# evalsoc register map
Vendor: Nuclei; Series: Nuclei Evaluation SoC
CPU: Evalsoc, little endian
Registers are 32-bit, read-write, reset 0x0 unless marked. A register's access mark holds for its fields unless they carry their own. Offsets are from the block's base; [hi:lo] are bit positions; {n}, {i} and the like mark numbered series; 'fields as' and 'values as' point back to an identical list.

## SMP — Address space of SMP and Cluster Cache. Nuclei Processor Core can optionally support Cluster Cache (CC) and Symmetric Multi-Processor (SMP).
Base 0x18040000
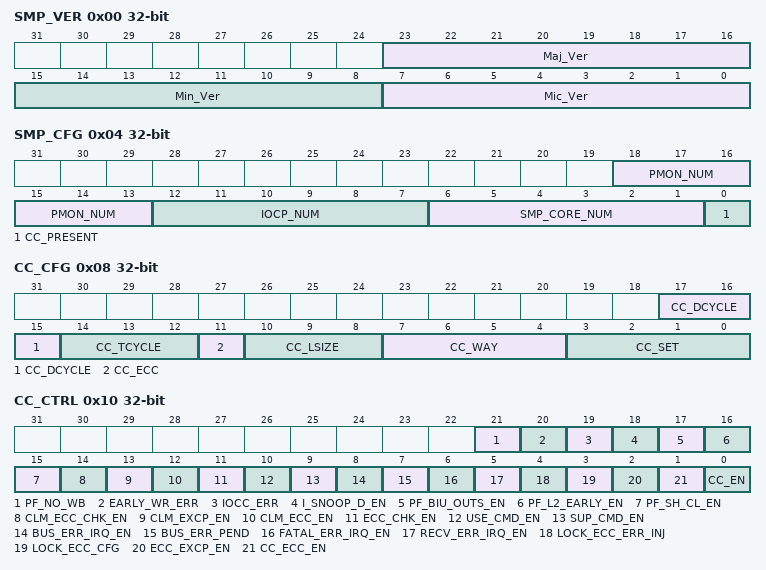
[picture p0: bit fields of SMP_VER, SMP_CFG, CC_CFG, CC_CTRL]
0x00 SMP_VER ro — Machine Mode SMP Version Register. Shows the microarchitecture implementation version of SMP related module.
  [23:16] Maj_Ver — Major Version Number
  [15:8] Min_Ver — Minor Version Number
  [7:0] Mic_Ver — Micro Version Number
0x04 SMP_CFG ro — Machine Mode SMP Configuration Register. Shows the hardware configuration of SMP related design.
  [18:13] PMON_NUM — The performance monitor number, it is fixed value when the RTL is generated.
  [12:7] IOCP_NUM — The IO Coherency port number in the cluster, it is fixed value when the RTL is generated.
  [6:1] SMP_CORE_NUM — Indicate core number in the cluster, it is fixed value (smp_core_num -1) when the RTL is generated.
  [0] CC_PRESENT — Cluster Cache present or not. 0: not present; 1: Present
0x08 CC_CFG ro — Machine Mode CC Config Register. Shows the hardware configuration of Cluster Cache.
  [17:15] CC_DCYCLE — Indicate the L2 Data sram access cycle - 1. 0: 1-cycle, 1: 2-cycle
  [14:12] CC_TCYCLE — Indicate the L2 Tag sram access cycle - 1. 0: 1-cycle, 1: 2-cycle
  [11] CC_ECC — Indicate the Cluster Cache supports ECC or not
  [10:8] CC_LSIZE — Cluster Cache Line Size = 2^(CC_LSIZE + 2)
  [7:4] CC_WAY — Cluster Cache Way Number = (CC_WAY + 1)
  [3:0] CC_SET — Cluster Cache Set Number = 2^(CC_SET)
0x0C SMP_ENB — Machine Mode SMP Enable Register. Controls which cores or all IOCP in the cluster can be cache coherency with each other handled by hardware.
  [15:0] SMP_Enable — SMP Enable Bit for clients in the Cluster. Each bit control one client. The low bit is CORE clients, high bit is IOCP clients.
0x10 CC_CTRL — Machine Mode CC Control Register. Controls Cluster Cache specific functions and gets some status.
  [21] PF_NO_WB — Enable L2 prefetch to abort and avoid dirty cacheline write back. 0: Disable, 1: Enable
  [20] EARLY_WR_ERR ro — Early write response has error. 0: No error, 1: Error
  [19] IOCC_ERR ro — IOCC Has error. 0: No error, 1: Error
  [18] I_SNOOP_D_EN — Snoop to dcache for icache refill reads Enable. 0: Disable, 1: Enable (default in smp cores)
  [17] PF_BIU_OUTS_EN — Enable the limit of outstanding L2 Prefetch. 0: Disable, 1: Enable
  [16] PF_L2_EARLY_EN — Enable L2 prefetch to initialize external bus read access while lookup the cluster cache. 0: Disable, 1: Enable
  [15] PF_SH_CL_EN — Enable L1 prefetch to snoop and share cacheline from other cores. 0: Disable, 1: Enable
  [14] CLM_ECC_CHK_EN — CLM ECC Check Enable Bit. 0: Disable, 1: Enable
  [13] CLM_EXCP_EN — CLM ECC Exception Enable Bit. 0: Disable, 1: Enable
  [12] CLM_ECC_EN — CLM ECC Enable Bit. 0: Disable, 1: Enable
  [11] ECC_CHK_EN — CC ECC Check Enable Bit. 0: Disable, 1: Enable
  [10] USE_CMD_EN — Enable U Mode can operate register CC_uCMD and SMP_PMON_SEL. 0: Disable, 1: Enable
  [9] SUP_CMD_EN — Enable S Mode can operate register CC_sCMD and SMP_PMON_SEL. 0: Disable, 1: Enable
  [8] BUS_ERR_IRQ_EN — Enable the Bus Error interrupt of CC maintain operation. 0: Disable, 1: Enable
  [7] BUS_ERR_PEND ro — Indicate if there is Bus Error Pending of all type. 0: No Pending, 1: Pending.
  [6] FATAL_ERR_IRQ_EN — Enable the interrupt when fatal error count exceeds the threshold. 0: Disable, 1: Enable
  [5] RECV_ERR_IRQ_EN — Enable the interrupt when recoverable error count exceeds the threshold. 0: Disable, 1: Enable
  [4] LOCK_ECC_ERR_INJ — Lock CC ECC Error Injection Register. 0: Disable, 1: Enable.
  [3] LOCK_ECC_CFG — Lock the CC ECC Configuration Bit. 0: Disable, 1: Enable. If set to 1, previous bits can't be changed.
  [2] ECC_EXCP_EN — CC ECC Exception Enable Bit. 0: Disable, 1: Enable
  [1] CC_ECC_EN — CC ECC Enable Bit. 0: Disable, 1: Enable
  [0] CC_EN — CC Enable Bit. 0: Disable, 1: Enable
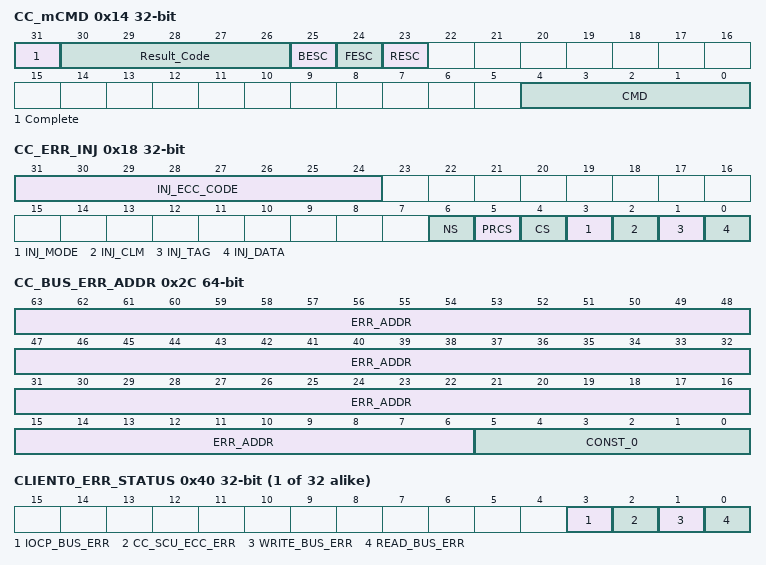
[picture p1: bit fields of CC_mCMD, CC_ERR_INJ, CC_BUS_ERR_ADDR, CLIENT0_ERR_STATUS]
0x14 CC_mCMD — Machine Mode CC Command and Status. Sets specific maintain command for Cluster Cache and checks the command result in Machine Mode.
  [31] Complete ro — Indicate the CMD complete or not. 0: Not Complete, 1: Complete
  [30:26] Result_Code ro — Result of the CMD
  [25] BESC — Read as BUS_ERR_PEND, write 1 will clear BUS_ERR_PEND.
  [24] FESC — Read as Fatal ECC Error IRQ Pending, write 1 will clear CC_FATAL_CNT.
  [23] RESC — Read as Recoverable ECC Error IRQ Pending, write 1 will clear CC_RECV_CNT.
  [4:0] CMD — Cluster Cache Maintain Command Code
0x18 CC_ERR_INJ — CC ECC Error Injection Control Register.
  [31:24] INJ_ECC_CODE — The content which will be injected
  [6] NS — Secure mode and Non secure mode. 0: secure mode, 1: non secure mode
  [5] PRCS ro — Precise injection error flag.
  [4] CS — Precise injection error control and status. Write 1 to start, automatic cleared when finished.
  [3] INJ_MODE — Indicate the software ecc code inject mode. 0: Direct Write Mode, 1: XOR Write Mode.
  [2] INJ_CLM — Inject error to CLM Ram
  [1] INJ_TAG — Inject error to CC Tag Ram
  [0] INJ_DATA — Inject error to CC Data Ram
0x1C CC_RECV_CNT — CC ECC Recoverable Error Count Register. Counts the Cluster Cache ECC recoverable error events.
  [15:0] CNT — Count the recoverable error, it is saturated
0x20 CC_FATAL_CNT — CC ECC Fatal Error Count Register. Counts the Cluster Cache ECC fatal error events.
  [15:0] CNT — Count the fatal error, it is saturated
0x24 CC_RECV_THV — CC ECC Recoverable Error Threshold Register. Sets the threshold value of Cluster Cache ECC recoverable errors.
  [15:0] THRESHOLD — The threshold value of ECC recoverable error.
0x28 CC_FATAL_THV — CC ECC Fatal Error Threshold Register. Sets the threshold value of Cluster Cache ECC fatal error.
  [15:0] THRESHOLD — The threshold value of ECC fatal error.
0x2C CC_BUS_ERR_ADDR 64-bit (reset mask 0xFFFFFFFF) — CC Maintain Operate Bus Error Physical Address. Records the Physical Address when CC Management Operation causes Bus Error.
  [63:6] ERR_ADDR — The error address when Bus Error happens.
  [5:0] CONST_0 ro — Constant 0. Width depends on cache line size.
{0x40+4i} CLIENT{i}_ERR_STATUS (i=0..31) — Client{i} of CC Error Status. Records the detail error type for the client.
  [3] IOCP_BUS_ERR — The error type is IOCP Bus response error. Only applies to clients hooked to IOCP Ports.
  [2] CC_SCU_ECC_ERR — The error type is cluster cache tag/data, SCU shadow tag or snoop L1 access ECC error.
  [1] WRITE_BUS_ERR — The error type is write bus error.
  [0] READ_BUS_ERR — The error type is read bus error.
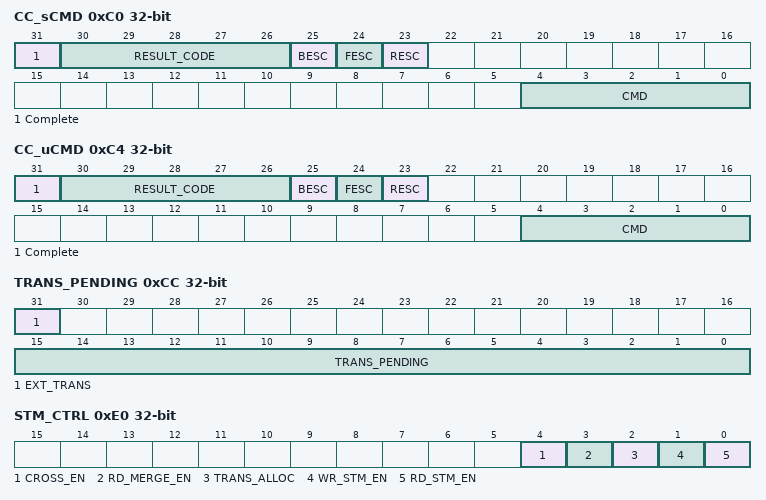
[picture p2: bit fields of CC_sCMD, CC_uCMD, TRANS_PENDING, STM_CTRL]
0xC0 CC_sCMD — Supervisor Mode CC Command and Status. Sets specific maintain command for Cluster Cache and checks the command result in Supervisor Mode.
  [31] Complete ro — Indicate the CMD complete or not. 0: Not Complete, 1: Complete
  [30:26] RESULT_CODE ro — Result of the CMD
  [25] BESC — Read as BUS_ERR_PEND, write 1 will clear BUS_ERR_PEND.
  [24] FESC — Read as Fatal ECC Error IRQ Pending, write 1 will clear CC_FATAL_CNT.
  [23] RESC — Read as Recoverable ECC Error IRQ Pending, write 1 will clear CC_RECV_CNT.
  [4:0] CMD — Cluster Cache Maintain Command Code
0xC4 CC_uCMD — User Mode CC Command and Status. Sets specific maintain command for Cluster Cache and checks the command result in User Mode.
  fields as CC_sCMD
0xC8 SNOOP_PENDING ro — Indicate the Core is being snooped or not in the SCU.
  [15:0] SNOOP_PENDING — Snoop pending bit for each client in the cluster.
0xCC TRANS_PENDING ro — Indicate the Core's transaction finish or not in the SCU.
  [31] EXT_TRANS — External Memory Bus Transaction pending bit.
  [15:0] TRANS_PENDING — Transaction pending bit for each core in the cluster.
0xD0 CLM_ADDR_BASE 64-bit (reset mask 0xFFFFFFFF) — Cluster Local Memory base address register. Sets the base address of CLM. Aligned to Cluster Cache size.
  [63:0] ADDR — The base address of CLM.
0xD8 CLM_WAY_EN — Cluster Cache way enable register for Cluster Local Memory. Sets the data ram of Cluster Cache to be used as CLM.
  [15:0] ENA — This way is used as CLM or not.
0xDC CC_INVALID_ALL — Cluster Cache invalid all register. Invalidates all Cluster Cache without affecting CLM.
  [0] CS wo — Write 1 will invalid all Cluster Cache, hardware clears when done.
0xE0 STM_CTRL — Stream read/write control register.
  [4] CROSS_EN — Read stream cross 4K enable.
  [3] RD_MERGE_EN — Non-cacheable attribute read merge Enable.
  [2] TRANS_ALLOC — Translate allocate attribute to non-alloc attribute Enable.
  [1] WR_STM_EN — Write stream Enable.
  [0] RD_STM_EN — Read stream Enable.
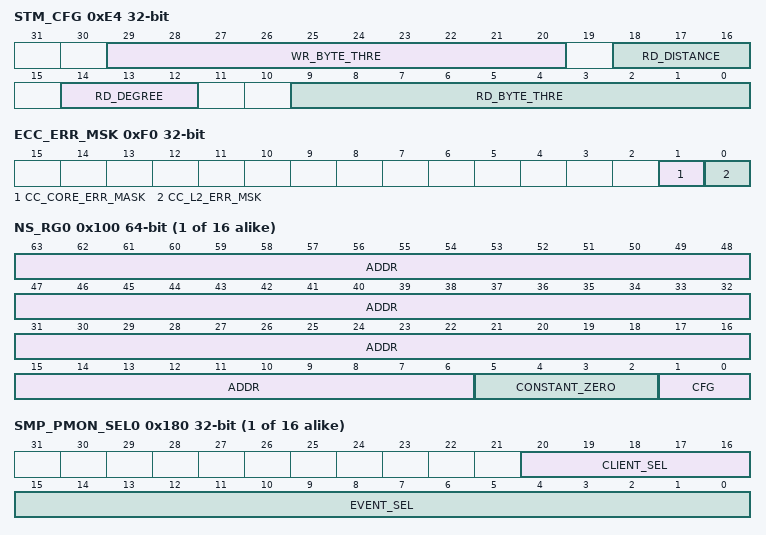
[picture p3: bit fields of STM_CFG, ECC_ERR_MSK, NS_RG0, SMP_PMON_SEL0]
0xE4 STM_CFG — Stream read/write configuration register.
  [29:20] WR_BYTE_THRE — The line buff timeout free time when no same cacheline transaction.
  [18:16] RD_DISTANCE — The threshold bytes number matching write stream training successfully.
  [14:12] RD_DEGREE — The delta between prefetch address and current bus address.
  [9:0] RD_BYTE_THRE — The prefetch number for Read stream.
0xE8 STM_TIMEOUT — Stream read/write timeout register.
  [10:0] TIMEOUT — write streaming wait clk num
0xEC DFF_PROT — Hardware Register protect Enable register.
  [1:0] CHK_EN — Register protect check enable. 2'b01: Disable, 2'b10: Enable, Other: illegal value.
0xF0 ECC_ERR_MSK — Mask L2M ECC Error to ecc_cc_error_masked or safety_error output.
  [1] CC_CORE_ERR_MASK — Mask Core double bit error output. 0: Not mask, 1: Mask
  [0] CC_L2_ERR_MSK — Mask L2 double bit error output. 0: Not mask, 1: Mask
{0x100+8i} NS_RG{i} 64-bit (reset mask 0xFFFFFFFF) (i=0..15) — Non-Sharable Memory Region {i} register.
  [63:6] ADDR — Coding of address and space of the region
  [5:2] CONSTANT_ZERO ro — Constant 0. Granularity of the region equals to cacheline size.
  [1:0] CFG — 0: Disable this region; 2: NACL; 3: NAPOT.
{0x180+4i} SMP_PMON_SEL{i} (i=0..15) — Performance Monitor Event Selector {i}. Selects Cluster Cache micro-architecture event to monitor performance.
  [20:16] CLIENT_SEL — Specify the core in the cluster or external master number hooked to I/O Coherency Port
  [15:0] EVENT_SEL — Select the event for this Performance Monitor Counter
{0x1C0+8i} SMP_PMON_CNT{i} 64-bit (reset mask 0xFFFFFFFF) (i=0..15) — Performance Monitor Event Counter {i}. Counts the event as the corresponding selector register selects.
  [63:0] CNT — If the event selected happens once, the value adds 1. Overflow sets Overflow bit in selector register.
{0x280+8i} CLIENT{i}_ERR_ADDR 64-bit (reset mask 0xFFFFFFFF) (i=0..31) — The register of address of client{i} which causes error.
  [63:0] ERR_ADDR — The error address when Error happens for the client.
{0x380+4i} CLIENT{i}_WAY_MASK (i=0..31) — Cluster Cache way mask control register for client{i}. Sets the Cluster Cache ways which can be used by the client.
  [15:0] MASK — Mask this way for the client. If bit n is 1, this way can't be used by this client.
0x720 CC_INV_RANGE — Cluster invalidate address range control and status.
  [0] CS — Write 1 to start inv range, automatic cleared when finished.
0x724 CC_INV_RANGE_START 64-bit (reset mask 0xFFFFFFFF) — Cluster invalidate address range start address.
  [63:0] ADDR — Set inv range start address.
0x72C CC_INV_RANGE_END 64-bit (reset mask 0xFFFFFFFF) — Cluster invalidate address range end address.
  [63:0] ADDR — Set inv range end address.
0x740 CC_ECC_INJ_WAY — Precise injection error WAY number. Must be one-hot encoding.
  [15:0] NUM — Set precise ecc inject way number. (Must one-hot)
0x744 CC_ECC_INJ_ADDR 64-bit (reset mask 0xFFFFFFFF) — Precise injection error address.
  [63:0] ADDR — Set precise ecc inject address.
0x74C CC_ECC_INJ_DATA — Precise injection error data.
  [31:0] DATA — Set precise ecc inject data.
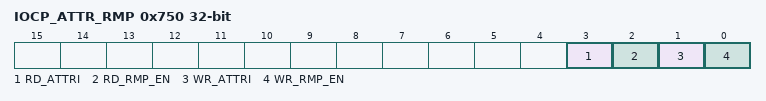
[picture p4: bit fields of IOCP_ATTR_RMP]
0x750 IOCP_ATTR_RMP — Iocp attribute remap register. Sets iocp read and write operation attribute remap.
  [3] RD_ATTRI — Remap allocate and non-alloc. 0: Remap non-alloc to allocate, 1: Remap allocate to non-alloc
  [2] RD_RMP_EN — Set read trans attribute remap enable.
  [1] WR_ATTRI — Remap allocate and non-alloc. 0: Remap non-alloc to allocate, 1: Remap allocate to non-alloc
  [0] WR_RMP_EN — Set write trans attribute remap enable.
